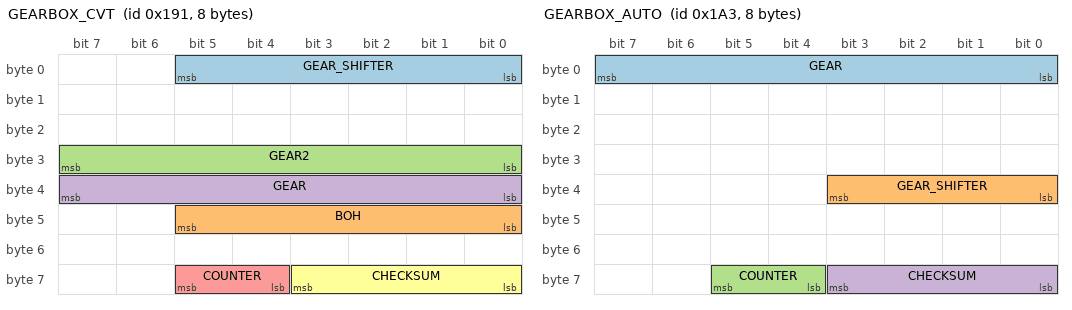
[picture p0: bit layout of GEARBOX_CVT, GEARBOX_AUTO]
BO_ 401 GEARBOX_CVT: 8 PCM
 SG_ GEAR_SHIFTER : 5|6@0+ (1,0) [0|63] "" EON
 SG_ BOH : 45|6@0+ (1,0) [0|63] "" XXX
 SG_ GEAR2 : 31|8@0+ (1,0) [0|1] "" XXX
 SG_ GEAR : 39|8@0+ (1,0) [0|255] "" XXX
 SG_ COUNTER : 61|2@0+ (1,0) [0|3] "" EON
 SG_ CHECKSUM : 59|4@0+ (1,0) [0|15] "" EON

BO_ 419 GEARBOX_AUTO: 8 PCM
 SG_ GEAR : 7|8@0+ (1,0) [0|256] "" EON
 SG_ GEAR_SHIFTER : 35|4@0+ (1,0) [0|15] "" EON
 SG_ COUNTER : 61|2@0+ (1,0) [0|3] "" EON
 SG_ CHECKSUM : 59|4@0+ (1,0) [0|3] "" EON

VAL_ 401 GEAR_SHIFTER 32 "L" 16 "S" 8 "D" 4 "N" 2 "R" 1 "P" ;
VAL_ 401 GEAR 7 "L" 10 "S" 4 "D" 3 "N" 2 "R" 1 "P" ;
VAL_ 419 GEAR_SHIFTER  32 "D" 16 "N" 8 "R" 4 "P" 0 "B" ;
